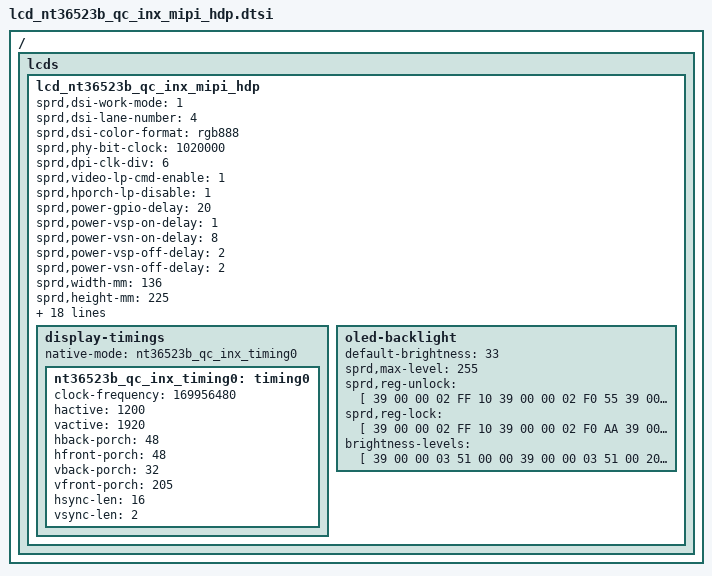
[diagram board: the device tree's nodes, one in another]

/ {
	fragment {
		target-path = "/";
		__overlay__ {
			lcds {
				lcd_nt36523b_qc_inx_mipi_hdp: lcd_nt36523b_qc_inx_mipi_hdp {

					sprd,dsi-work-mode = <1>; /* video burst mode*/
					sprd,dsi-lane-number = <4>;
					sprd,dsi-color-format = "rgb888";

					sprd,phy-bit-clock = <1020000>;	/* kbps */
					sprd,dpi-clk-div = <6>;
					sprd,video-lp-cmd-enable = <1>;
					sprd,hporch-lp-disable = <1>;
					sprd,power-gpio-delay = <20>;/* ms */
					sprd,power-vsp-on-delay = <1>;
					sprd,power-vsn-on-delay = <8>;
					sprd,power-vsp-off-delay = <2>;
					sprd,power-vsn-off-delay = <2>;

					sprd,width-mm = <136>;
					sprd,height-mm = <225>;

					sprd,reset-on-sequence = <1 10>, <0 5>, <1 5>, <0 5>, <1 10>;
					sprd,reset-off-sequence = <1 5>;

					sprd,esd-check-enable = <1>;
					sprd,esd-check-mode = <0>;
					sprd,esd-check-reg-count = <2>;
					sprd,esd-check-register = [0A AB];
					sprd,esd-check-value-len = <1 2>;
					sprd,esd-check-value = [9C 00 00];
					sprd,esd-check-period = <2000>;

					sprd,initial-command = [
							39 00 00 02 FF 20
							39 00 00 02 FB 01
							39 00 00 02 01 55
							39 00 00 02 05 D1
							39 00 00 02 07 87
							39 00 00 02 08 61
							39 00 00 02 0E 7D
							39 00 00 02 0F 7F
							39 00 00 02 94 C0
							39 00 00 02 95 09
							39 00 00 02 96 09
							39 00 00 02 9D 00
							39 00 00 02 9E 00
							39 00 00 02 69 98
							39 00 00 02 75 A2
							39 00 00 02 77 B3
							39 00 00 02 0D 63
							39 00 00 02 58 60
							39 00 00 02 FF 24
							39 00 00 02 FB 01
							39 00 00 02 91 44
							39 00 00 02 92 7B
							39 00 00 02 93 CD
							39 00 00 02 94 22
							39 00 00 02 60 96
							39 00 00 02 61 80
							39 00 00 02 63 70
							39 00 00 02 C2 CC
							39 00 00 02 00 03
							39 00 00 02 01 03
							39 00 00 02 02 03
							39 00 00 02 03 03
							39 00 00 02 04 03
							39 00 00 02 05 03
							39 00 00 02 06 03
							39 00 00 02 07 03
							39 00 00 02 08 22
							39 00 00 02 09 06
							39 00 00 02 0A 05
							39 00 00 02 0B 1D
							39 00 00 02 0C 1C
							39 00 00 02 0D 11
							39 00 00 02 0E 10
							39 00 00 02 0F 0F
							39 00 00 02 10 0E
							39 00 00 02 11 0D
							39 00 00 02 12 0C
							39 00 00 02 13 04
							39 00 00 02 14 03
							39 00 00 02 15 03
							39 00 00 02 16 03
							39 00 00 02 17 03
							39 00 00 02 18 03
							39 00 00 02 19 03
							39 00 00 02 1A 03
							39 00 00 02 1B 03
							39 00 00 02 1C 03
							39 00 00 02 1D 03
							39 00 00 02 1E 22
							39 00 00 02 1F 06
							39 00 00 02 20 05
							39 00 00 02 21 1D
							39 00 00 02 22 1C
							39 00 00 02 23 11
							39 00 00 02 24 10
							39 00 00 02 25 0F
							39 00 00 02 26 0E
							39 00 00 02 27 0D
							39 00 00 02 28 0C
							39 00 00 02 29 04
							39 00 00 02 2A 03
							39 00 00 02 2B 03
							39 00 00 02 2F 04
							39 00 00 02 30 32
							39 00 00 02 31 41
							39 00 00 02 33 32
							39 00 00 02 34 04
							39 00 00 02 35 41
							39 00 00 02 37 44
							39 00 00 02 38 40
							39 00 00 02 39 00
							39 00 00 02 3A 00
							39 00 00 02 3B 5B
							39 00 00 02 3D 93
							39 00 00 02 AB 44
							39 00 00 02 AC 40
							39 00 00 02 4D 21
							39 00 00 02 4E 43
							39 00 00 02 4F 65
							39 00 00 02 51 56
							39 00 00 02 52 34
							39 00 00 02 53 12
							39 00 00 03 55 83 03
							39 00 00 02 56 06
							39 00 00 02 58 21
							39 00 00 02 59 40
							39 00 00 02 5A 00
							39 00 00 02 5B 5B
							39 00 00 03 5E 00 0C
							39 00 00 02 5F 00
							39 00 00 02 7A 00
							39 00 00 02 7B 00
							39 00 00 02 7C 00
							39 00 00 02 7D 00
							39 00 00 02 7E 20
							39 00 00 02 7F 3C
							39 00 00 02 80 00
							39 00 00 02 81 00
							39 00 00 02 82 08
							39 00 00 02 97 02
							39 00 00 02 C5 10
							39 00 00 02 D7 55
							39 00 00 02 D8 55
							39 00 00 02 D9 23
							39 00 00 02 DA 05
							39 00 00 02 DB 01
							39 00 00 02 DC 7B
							39 00 00 02 DD 55
							39 00 00 02 DE 27
							39 00 00 0D B6 05 00 05 00 00 00 00 00 05 05 00 00
							39 00 00 02 FF 25
							39 00 00 02 FB 01
							39 00 00 02 13 02
							39 00 00 02 14 E5
							39 00 00 02 FF 26
							39 00 00 02 FB 01
							39 00 00 02 00 A0
							39 00 00 02 02 31
							39 00 00 02 04 28
							39 00 00 02 0A F2
							39 00 00 02 06 20
							39 00 00 02 0C 13
							39 00 00 02 0D 0A
							39 00 00 02 0F 0A
							39 00 00 02 11 00
							39 00 00 02 12 50
							39 00 00 02 13 26
							39 00 00 02 14 61
							39 00 00 02 15 00
							39 00 00 02 16 10
							39 00 00 02 17 A0
							39 00 00 02 18 86
							39 00 00 02 19 0C
							39 00 00 02 1A 00
							39 00 00 02 1B 0C
							39 00 00 02 1C 00
							39 00 00 02 2A 0C
							39 00 00 02 2B 00
							39 00 00 02 20 00
							39 00 00 02 FF 27
							39 00 00 02 FB 01
							39 00 00 02 C0 18
							39 00 00 02 C1 00
							39 00 00 02 C2 00
							39 00 00 02 56 00
							39 00 00 02 58 80
							39 00 00 02 59 50
							39 00 00 02 5A 00
							39 00 00 02 5B 14
							39 00 00 02 5C 00
							39 00 00 02 5D 01
							39 00 00 02 5E 20
							39 00 00 02 5F 10
							39 00 00 02 60 00
							39 00 00 02 61 1B
							39 00 00 02 62 00
							39 00 00 02 63 01
							39 00 00 02 64 22
							39 00 00 02 65 1A
							39 00 00 02 66 00
							39 00 00 02 67 01
							39 00 00 02 68 23
							39 00 00 02 78 80
							39 00 00 02 79 00
							39 00 00 02 7A 00
							39 00 00 02 7B CC
							39 00 00 02 7C 00
							39 00 00 02 7D 0C
							39 00 00 02 7E B3
							39 00 00 02 7F 10
							39 00 00 02 98 01
							39 00 00 02 B4 03
							39 00 00 02 9B BE
							39 00 00 02 A0 90
							39 00 00 02 AB 28
							39 00 00 02 BC 0C
							39 00 00 02 BD 28
							39 00 00 02 FF 2A
							39 00 00 02 FB 01
							39 00 00 02 F1 03
							39 00 00 02 23 09
							39 00 00 02 24 00
							39 00 00 02 25 7B
							39 00 00 02 26 F8
							39 00 00 02 27 00
							39 00 00 02 28 1A
							39 00 00 02 29 00
							39 00 00 02 2A 1A
							39 00 00 02 2B 00
							39 00 00 02 2D 1A
							39 00 00 02 2F 00
							39 00 00 02 30 98
							39 00 00 02 31 FF
							39 00 00 02 32 00
							39 00 00 02 33 CD
							39 00 00 02 34 00
							39 00 00 02 35 CD
							39 00 00 02 36 00
							39 00 00 02 37 CD
							39 00 00 02 64 96
							39 00 00 02 65 00
							39 00 00 02 66 00
							39 00 00 02 6A 96
							39 00 00 02 6B 00
							39 00 00 02 6C 00
							39 00 00 02 70 92
							39 00 00 02 71 00
							39 00 00 02 72 00
							39 00 00 02 A2 33
							39 00 00 02 A3 30
							39 00 00 02 A4 C0
							39 00 00 02 E8 00
							39 00 00 02 97 3C
							39 00 00 02 98 02
							39 00 00 02 99 95
							39 00 00 02 9A 06
							39 00 00 02 9B 00
							39 00 00 02 9C 0B
							39 00 00 02 9D 0A
							39 00 00 02 9E 90
							39 00 00 02 FF 20
							39 00 00 02 FB 01
							39 00 00 11 B0 00 00 00 10 00 30 00 4A 00 63 00 78 00 8C 00 9E
							39 00 00 11 B1 00 AF 00 E6 01 14 01 57 01 8B 01 DB 02 1B 02 1D
							39 00 00 11 B2 02 5A 02 9E 02 C9 02 FF 03 24 03 53 03 60 03 6F
							39 00 00 0D B3 03 7D 03 8A 03 8C 03 8E 03 8F 03 90
							39 00 00 11 B4 00 00 00 12 00 35 00 51 00 6D 00 84 00 99 00 AB
							39 00 00 11 B5 00 BD 00 F6 01 22 01 63 01 97 01 E6 02 26 02 27
							39 00 00 11 B6 02 62 02 A4 02 CE 03 06 03 29 03 54 03 62 03 73
							39 00 00 0D B7 03 7E 03 8B 03 8D 03 8E 03 8F 03 90
							39 00 00 11 B8 00 00 00 15 00 3E 00 5B 00 78 00 8E 00 A3 00 B5
							39 00 00 11 B9 00 C6 00 FD 01 27 01 69 01 9B 01 E8 02 28 02 29
							39 00 00 11 BA 02 64 02 A6 02 CF 03 06 03 27 03 54 03 63 03 77
							39 00 00 0D BB 03 86 03 88 03 8A 03 8C 03 8E 03 90
							39 00 00 02 FF 21
							39 00 00 02 FB 01
							39 00 00 11 B0 00 00 00 10 00 30 00 4A 00 63 00 78 00 8C 00 9E
							39 00 00 11 B1 00 AF 00 E6 01 14 01 57 01 8B 01 DB 02 1B 02 1D
							39 00 00 11 B2 02 5A 02 9E 02 C9 02 FF 03 24 03 53 03 60 03 6F
							39 00 00 0D B3 03 7D 03 8A 03 AD 03 BE 03 DA 03 ED
							39 00 00 11 B4 00 00 00 12 00 35 00 51 00 6D 00 84 00 99 00 AB
							39 00 00 11 B5 00 BD 00 F6 01 22 01 63 01 97 01 E6 02 26 02 27
							39 00 00 11 B6 02 62 02 A4 02 CE 03 06 03 29 03 54 03 62 03 73
							39 00 00 0D B7 03 7E 03 8B 03 AE 03 BE 03 DA 03 ED
							39 00 00 11 B8 00 00 00 15 00 3E 00 5B 00 78 00 8E 00 A3 00 B5
							39 00 00 11 B9 00 C5 00 FD 01 27 01 69 01 9B 01 E8 02 28 02 29
							39 00 00 11 BA 02 64 02 A6 02 CF 03 06 03 27 03 54 03 63 03 77
							39 00 00 0D BB 03 86 03 A2 03 AC 03 BC 03 D9 03 ED
							39 00 00 02 FF 23
							39 00 00 02 FB 01
							39 00 00 02 00 80
							39 00 00 02 07 00
							39 00 00 02 FF 25
							39 00 00 02 FB 01
							39 00 00 02 17 C2
							39 00 00 02 19 1F
							39 00 00 02 1B 5B
							39 00 00 02 1D 00
							39 00 00 02 FF F0
							39 00 00 02 FB 01
							39 00 00 02 3A 08
							39 00 00 02 FF D0
							39 00 00 02 FB 01
							39 00 00 02 02 A7
							39 00 00 02 09 BF
							39 00 00 02 FF 10
							39 00 00 02 B9 01
							39 00 00 02 FF 20
							39 00 00 02 18 40
							39 00 00 02 FF 10
							39 00 00 02 B9 02
							39 00 00 02 FF 2A
							39 00 00 02 FB 01
							39 00 00 02 F1 03
							39 00 00 02 FF 10
							39 00 00 02 FB 01
							39 00 00 02 53 2C
							39 00 00 03 51 00 00
							39 00 00 03 68 05 01
							39 00 00 06 3B 03 22 CD 04 04
							39 00 00 02 35 00
							39 00 00 02 36 03
							39 00 00 02 B0 01
							05 64 00 01 11
							05 05 00 01 29
							39 00 00 02 F0 55
							39 00 00 02 F1 AA
							39 00 00 02 F2 66
							];

					sprd,sleep-in-command = [
						39 00 00 02 FF 10
						39 00 00 02 F0 AA
						39 00 00 02 F1 55
						39 00 00 02 F2 99
						05 32 00 01 28
						05 78 00 01 10
					];

					sprd,sleep-out-command = [
						23 64 00 23 11 00
						23 05 00 23 29 00
						39 00 00 02 FF 10
						39 00 00 02 F0 55
						39 00 00 02 F1 AA
						39 00 00 02 F2 66
					];

					sprd,pwm-diming-off-command = [
						39 00 00 02 53 24
					];

					display-timings {
						native-mode = <&nt36523b_qc_inx_timing0>;
						nt36523b_qc_inx_timing0: timing0 {
						clock-frequency = <169956480>;
							hactive = <1200>;
							vactive = <1920>;
							hback-porch = <48>;
							hfront-porch = <48>;
							vback-porch = <32>;
							vfront-porch = <205>;
							hsync-len = <16>;
							vsync-len = <2>;

						};
					};

					oled-backlight {
						default-brightness = <33>;
						sprd,max-level = <255>;

						sprd,reg-unlock = [
							39 00 00 02 FF 10
							39 00 00 02 F0 55
							39 00 00 02 F1 AA
							39 00 00 02 F2 66
						];

						sprd,reg-lock = [
							39 00 00 02 FF 10
							39 00 00 02 F0 AA
							39 00 00 02 F1 55
							39 00 00 02 F2 99
						];

						brightness-levels = [
							39 00 00 03 51 00 00
							39 00 00 03 51 00 20
							39 00 00 03 51 00 30
							39 00 00 03 51 00 40
							39 00 00 03 51 00 50
							39 00 00 03 51 00 60
							39 00 00 03 51 00 70
							39 00 00 03 51 00 80
							39 00 00 03 51 00 90
							39 00 00 03 51 00 A0
							39 00 00 03 51 00 B0
							39 00 00 03 51 00 C0
							39 00 00 03 51 00 D0
							39 00 00 03 51 00 E0
							39 00 00 03 51 00 F0
							39 00 00 03 51 01 00
							39 00 00 03 51 01 11
							39 00 00 03 51 01 21
							39 00 00 03 51 01 31
							39 00 00 03 51 01 41
							39 00 00 03 51 01 51
							39 00 00 03 51 01 61
							39 00 00 03 51 01 71
							39 00 00 03 51 01 81
							39 00 00 03 51 01 91
							39 00 00 03 51 01 A1
							39 00 00 03 51 01 B1
							39 00 00 03 51 01 C1
							39 00 00 03 51 01 D1
							39 00 00 03 51 01 E1
							39 00 00 03 51 01 F1
							39 00 00 03 51 02 01
							39 00 00 03 51 02 11
							39 00 00 03 51 02 22
							39 00 00 03 51 02 32
							39 00 00 03 51 02 42
							39 00 00 03 51 02 52
							39 00 00 03 51 02 62
							39 00 00 03 51 02 72
							39 00 00 03 51 02 82
							39 00 00 03 51 02 92
							39 00 00 03 51 02 A2
							39 00 00 03 51 02 B2
							39 00 00 03 51 02 C2
							39 00 00 03 51 02 D2
							39 00 00 03 51 02 E2
							39 00 00 03 51 02 F2
							39 00 00 03 51 03 02
							39 00 00 03 51 03 12
							39 00 00 03 51 03 22
							39 00 00 03 51 03 32
							39 00 00 03 51 03 43
							39 00 00 03 51 03 53
							39 00 00 03 51 03 63
							39 00 00 03 51 03 73
							39 00 00 03 51 03 83
							39 00 00 03 51 03 93
							39 00 00 03 51 03 A3
							39 00 00 03 51 03 B3
							39 00 00 03 51 03 C3
							39 00 00 03 51 03 D3
							39 00 00 03 51 03 E3
							39 00 00 03 51 03 F3
							39 00 00 03 51 04 03
							39 00 00 03 51 04 13
							39 00 00 03 51 04 23
							39 00 00 03 51 04 33
							39 00 00 03 51 04 43
							39 00 00 03 51 04 54
							39 00 00 03 51 04 64
							39 00 00 03 51 04 74
							39 00 00 03 51 04 84
							39 00 00 03 51 04 94
							39 00 00 03 51 04 A4
							39 00 00 03 51 04 B4
							39 00 00 03 51 04 C4
							39 00 00 03 51 04 D4
							39 00 00 03 51 04 E4
							39 00 00 03 51 04 F4
							39 00 00 03 51 05 04
							39 00 00 03 51 05 14
							39 00 00 03 51 05 24
							39 00 00 03 51 05 34
							39 00 00 03 51 05 44
							39 00 00 03 51 05 54
							39 00 00 03 51 05 65
							39 00 00 03 51 05 75
							39 00 00 03 51 05 85
							39 00 00 03 51 05 95
							39 00 00 03 51 05 A5
							39 00 00 03 51 05 B5
							39 00 00 03 51 05 C5
							39 00 00 03 51 05 D5
							39 00 00 03 51 05 E5
							39 00 00 03 51 05 F5
							39 00 00 03 51 06 05
							39 00 00 03 51 06 15
							39 00 00 03 51 06 25
							39 00 00 03 51 06 35
							39 00 00 03 51 06 45
							39 00 00 03 51 06 55
							39 00 00 03 51 06 65
							39 00 00 03 51 06 76
							39 00 00 03 51 06 86
							39 00 00 03 51 06 96
							39 00 00 03 51 06 A6
							39 00 00 03 51 06 B6
							39 00 00 03 51 06 C6
							39 00 00 03 51 06 D6
							39 00 00 03 51 06 E6
							39 00 00 03 51 06 F6
							39 00 00 03 51 07 06
							39 00 00 03 51 07 16
							39 00 00 03 51 07 26
							39 00 00 03 51 07 36
							39 00 00 03 51 07 46
							39 00 00 03 51 07 56
							39 00 00 03 51 07 66
							39 00 00 03 51 07 76
							39 00 00 03 51 07 87
							39 00 00 03 51 07 97
							39 00 00 03 51 07 A7
							39 00 00 03 51 07 B7
							39 00 00 03 51 07 C7
							39 00 00 03 51 07 D7
							39 00 00 03 51 07 E7
							39 00 00 03 51 07 F7
							39 00 00 03 51 08 07
							39 00 00 03 51 08 17
							39 00 00 03 51 08 27
							39 00 00 03 51 08 37
							39 00 00 03 51 08 47
							39 00 00 03 51 08 57
							39 00 00 03 51 08 67
							39 00 00 03 51 08 77
							39 00 00 03 51 08 87
							39 00 00 03 51 08 98
							39 00 00 03 51 08 A8
							39 00 00 03 51 08 B8
							39 00 00 03 51 08 C8
							39 00 00 03 51 08 D8
							39 00 00 03 51 08 E8
							39 00 00 03 51 08 F8
							39 00 00 03 51 09 08
							39 00 00 03 51 09 18
							39 00 00 03 51 09 28
							39 00 00 03 51 09 38
							39 00 00 03 51 09 48
							39 00 00 03 51 09 58
							39 00 00 03 51 09 68
							39 00 00 03 51 09 78
							39 00 00 03 51 09 88
							39 00 00 03 51 09 98
							39 00 00 03 51 09 A9
							39 00 00 03 51 09 B9
							39 00 00 03 51 09 C9
							39 00 00 03 51 09 D9
							39 00 00 03 51 09 E9
							39 00 00 03 51 09 F9
							39 00 00 03 51 0A 09
							39 00 00 03 51 0A 19
							39 00 00 03 51 0A 29
							39 00 00 03 51 0A 39
							39 00 00 03 51 0A 49
							39 00 00 03 51 0A 59
							39 00 00 03 51 0A 69
							39 00 00 03 51 0A 79
							39 00 00 03 51 0A 89
							39 00 00 03 51 0A 99
							39 00 00 03 51 0A A9
							39 00 00 03 51 0A BA
							39 00 00 03 51 0A CA
							39 00 00 03 51 0A DA
							39 00 00 03 51 0A EA
							39 00 00 03 51 0A FA
							39 00 00 03 51 0B 0A
							39 00 00 03 51 0B 1A
							39 00 00 03 51 0B 2A
							39 00 00 03 51 0B 3A
							39 00 00 03 51 0B 4A
							39 00 00 03 51 0B 5A
							39 00 00 03 51 0B 6A
							39 00 00 03 51 0B 7A
							39 00 00 03 51 0B 8A
							39 00 00 03 51 0B 9A
							39 00 00 03 51 0B AA
							39 00 00 03 51 0B BA
							39 00 00 03 51 0B CB
							39 00 00 03 51 0B DB
							39 00 00 03 51 0B EB
							39 00 00 03 51 0B FB
							39 00 00 03 51 0C 0B
							39 00 00 03 51 0C 1B
							39 00 00 03 51 0C 2B
							39 00 00 03 51 0C 3B
							39 00 00 03 51 0C 4B
							39 00 00 03 51 0C 5B
							39 00 00 03 51 0C 6B
							39 00 00 03 51 0C 7B
							39 00 00 03 51 0C 8B
							39 00 00 03 51 0C 9B
							39 00 00 03 51 0C AB
							39 00 00 03 51 0C BB
							39 00 00 03 51 0C CB
							39 00 00 03 51 0C DC
							39 00 00 03 51 0C EC
							39 00 00 03 51 0C FC
							39 00 00 03 51 0D 0C
							39 00 00 03 51 0D 1C
							39 00 00 03 51 0D 2C
							39 00 00 03 51 0D 3C
							39 00 00 03 51 0D 4C
							39 00 00 03 51 0D 5C
							39 00 00 03 51 0D 6C
							39 00 00 03 51 0D 7C
							39 00 00 03 51 0D 8C
							39 00 00 03 51 0D 9C
							39 00 00 03 51 0D AC
							39 00 00 03 51 0D BC
							39 00 00 03 51 0D CC
							39 00 00 03 51 0D DC
							39 00 00 03 51 0D ED
							39 00 00 03 51 0D FD
							39 00 00 03 51 0E 0D
							39 00 00 03 51 0E 1D
							39 00 00 03 51 0E 2D
							39 00 00 03 51 0E 3D
							39 00 00 03 51 0E 4D
							39 00 00 03 51 0E 5D
							39 00 00 03 51 0E 6D
							39 00 00 03 51 0E 7D
							39 00 00 03 51 0E 8D
							39 00 00 03 51 0E 9D
							39 00 00 03 51 0E AD
							39 00 00 03 51 0E BD
							39 00 00 03 51 0E CD
							39 00 00 03 51 0E DD
							39 00 00 03 51 0E ED
							39 00 00 03 51 0E FE
							39 00 00 03 51 0F 0E
							39 00 00 03 51 0F 1E
							39 00 00 03 51 0F 2E
							39 00 00 03 51 0F 3E
							39 00 00 03 51 0F 4E
							39 00 00 03 51 0F 5E
							39 00 00 03 51 0F 6E
							39 00 00 03 51 0F 7E
							39 00 00 03 51 0F 8E
							39 00 00 03 51 0F 9E
							39 00 00 03 51 0F AE
							39 00 00 03 51 0F BE
							39 00 00 03 51 0F CE
							39 00 00 03 51 0F DE
							39 00 00 03 51 0F EE
							39 00 00 03 51 0F FE
							39 00 00 03 51 0F FE
						];
					};
				};
			};
		};
	};
};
